# VPAC0_COMMON_0_IVPAC_TOP_0_CFG_SLV_PAR_VPAC_VISS0_S_VBUSP_MMR_CFG_VISS_TOP register map
Vendor: Texas Instruments
Peripheral module from a debugger description file (folder am62A).
Registers are 32-bit, read-write, reset 0x0 unless marked. A register's access mark holds for its fields unless they carry their own. Offsets are as the file gives them; lines under a group give offsets from that group; [hi:lo] are bit positions; {n}, {i} and the like mark numbered series; 'fields as' and 'values as' point back to an identical list; <NAME> marks a mode.

## VPAC0_COMMON_0_IVPAC_TOP_0_CFG_SLV_PAR_VPAC_VISS0_S_VBUSP_MMR_CFG_VISS_TOP
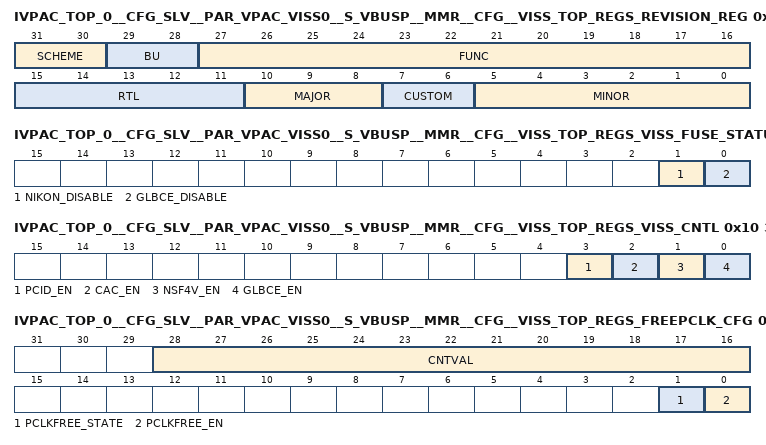
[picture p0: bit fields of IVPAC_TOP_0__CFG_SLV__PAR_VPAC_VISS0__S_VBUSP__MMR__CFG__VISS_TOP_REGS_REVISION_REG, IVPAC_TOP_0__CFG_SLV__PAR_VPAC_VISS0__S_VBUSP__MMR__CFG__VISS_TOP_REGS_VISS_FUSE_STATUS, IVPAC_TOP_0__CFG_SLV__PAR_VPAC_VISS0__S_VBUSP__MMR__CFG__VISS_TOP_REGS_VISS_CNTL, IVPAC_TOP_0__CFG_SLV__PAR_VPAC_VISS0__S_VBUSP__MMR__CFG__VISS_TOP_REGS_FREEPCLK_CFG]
0x00 IVPAC_TOP_0__CFG_SLV__PAR_VPAC_VISS0__S_VBUSP__MMR__CFG__VISS_TOP_REGS_REVISION_REG ro reset 0x64C40200 — VISS PID
  [31:30] SCHEME — Used to distinguish between old scheme and new scheme. Spare bit to encode future schemes
  [29:28] BU — BU indicator DSPS ==> 0x0 WTBU ==> 0x1 Processors ==> 0x2
  [27:16] FUNC — Function indicates a software compatible module family. If there is no level of software compatibility a new FUNC number, and hence PID, should be assigned.
  [15:11] RTL — RTL Version. R as described in PDR with additional clarifications and definitions below. Must be easily ECO-able or controlled during fabrication. Ideally through a top level metal mask or e-fuse. This number is maintained/owned by IP design owner. RTL follows a numbering such as X.Y.R.Z which are explained in this table. R changes ONLY when: (1) PDS uploads occur which may have been due to spec changes (2) Bug fixes occur (3) Resets to '0' when X or Y changes. Design team has an internal 'Z' (customer invisible) number which increments on every drop that happens due to DV and RTL updates. Z resets to 0 when R increments.
  [10:8] MAJOR — Major Revision. X as described in PDR with additional clarifications/definitions below. This number is owned/maintained by IP specification owner. X is part of IP numbering X.Y.R.Z. X changes ONLY when: (1) There is a major feature addition. An example would be adding Master Mode to Utopia Level2. The Func field (or Class/Type in old PID format) will remain the same. X does NOT change due to: (1) Bug fixes (2) Change in feature parameters.
  [7:6] CUSTOM — Indicates a special version for a particular device. Consequence of use may avoid use of standard Chip Support Library (CSL) / Drivers. 0 if non-custom.
  [5:0] MINOR — Minor Revision. Y as described in PDR with additional clarifications/definitions below. This number is owned/maintained by IP specification owner. Y changes ONLY when: (1) Features are scaled (up or down). Flexibility exists in that this feature scalability may either be represented in the Y change or a specific register in the IP that indicates which features are exactly available. (2) When feature creeps from Is-Not list to Is list. But this may not be the case once it sees silicon - in which case X will change. Y does NOT change due to: (1) Bug fixes (2) Typos or clarifications (3) major functional/feature change/addition/deletion. Instead these changes may be reflected via R, S, X as applicable. Spec owner maintains a customer-invisible number 'S' which changes due to: (1) Typos/clarifications (2) Bug documentation. Note that this bug is not due to a spec change but due to implementation. Nevertheless, the spec tracks the IP bugs. An RTL release (say for silicon PG1.1) that occurs due to bug fix should document the corresponding spec number (X.Y.S) in its release notes.
0x04 IVPAC_TOP_0__CFG_SLV__PAR_VPAC_VISS0__S_VBUSP__MMR__CFG__VISS_TOP_REGS_VISS_FUSE_STATUS ro — Register captures the Fuse control status. Shouldn't be captured into TRM
  [1] NIKON_DISABLE — Availability of NIKON specific feature HW in H3A. '0' -> Nikon features are available '1' -> Nikon features are not available
  [0] GLBCE_DISABLE — Availability GLBCE HW. '0' -> GLBCE function HW is available '1' -> GLBCE function HW is not available
0x08 IVPAC_TOP_0__CFG_SLV__PAR_VPAC_VISS0__S_VBUSP__MMR__CFG__VISS_TOP_REGS_VISS_LINEMEM_SIZE ro reset 0x1000 — Captures the no. of pixels per line supported by the VISS
  [13:0] LINEMEM_SZ — No. of pixels per line supported by the VISS HWAs Memories
0x0C IVPAC_TOP_0__CFG_SLV__PAR_VPAC_VISS0__S_VBUSP__MMR__CFG__VISS_TOP_REGS_SYSCONFIG — system Configuration
  [1] CLKCG_OVERIDE — Reserved for this HW version
0x10 IVPAC_TOP_0__CFG_SLV__PAR_VPAC_VISS0__S_VBUSP__MMR__CFG__VISS_TOP_REGS_VISS_CNTL — VISS top control
  [3] PCID_EN — '1' -> PCID is ON , '0' -> PCID is off i.e. bypass PCID. Read the bit status for completion of write. Even when '0', Configuration access to PCID will be successful.
  [2] CAC_EN — '1' -> CAC is ON , '0' -> CAC is off i.e. bypass CAC. Read the bit status for completion of write. Even when '0', Configuration access to CAC will be successful.
  [1] NSF4V_EN — '1' -> NSF4V is ON , '0' -> NSF4V is off i.e. bypass NSF4V. Read the bit status for completion of write. Even when '0', Configuration access to NSF4V will be successful.
  [0] GLBCE_EN — '1' -> GLBCE is ON , '0' -> GLBCE is off i.e. bypass GLBCE. Read the bit status for completion of write. When '0', Configuration access to GLBCE End points (MMR, Statastics memory ) will result in Error response.
0x14 IVPAC_TOP_0__CFG_SLV__PAR_VPAC_VISS0__S_VBUSP__MMR__CFG__VISS_TOP_REGS_FREEPCLK_CFG access per field — Register to control and configure Free running pixel clock to whole VISS pipe line
  [28:16] CNTVAL rw — Number of free pixel clocks to be provided
  [1] PCLKFREE_STATE ro — Status of Free running pixel clock state. 0 - Free running pixel Clock is not being provided currently 1 - Free running pixel Clock is getting provided
  [0] PCLKFREE_EN rw — Enable to provide Free running pixel clocks at the end of frame for VISS data pipe line. Needs to be enabled before end of a frame to provide free running pixel clock after that particular frame
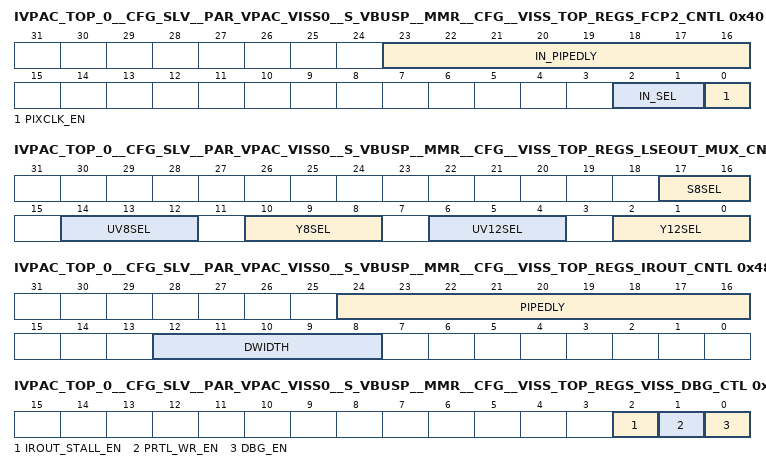
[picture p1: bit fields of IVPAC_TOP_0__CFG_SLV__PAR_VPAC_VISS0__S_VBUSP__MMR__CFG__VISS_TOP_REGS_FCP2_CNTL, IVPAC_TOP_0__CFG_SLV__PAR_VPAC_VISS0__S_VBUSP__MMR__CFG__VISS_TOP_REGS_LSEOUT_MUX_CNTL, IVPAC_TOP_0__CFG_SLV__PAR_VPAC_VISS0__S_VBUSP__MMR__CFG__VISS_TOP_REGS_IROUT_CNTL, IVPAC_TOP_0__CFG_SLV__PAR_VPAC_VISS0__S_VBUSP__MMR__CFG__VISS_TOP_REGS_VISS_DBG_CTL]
0x40 IVPAC_TOP_0__CFG_SLV__PAR_VPAC_VISS0__S_VBUSP__MMR__CFG__VISS_TOP_REGS_FCP2_CNTL — FCP2 Input Control register
  [23:16] IN_PIPEDLY — No. of pixel clock pipe delay on FCP2 input Vport. Used for matching with horizontal delay upto FCP Input
  [2:1] IN_SEL — Input path to FCP2. 0 - RFE output 1 - NSF4V output 2 - GLBCE output 3 - CAC output
  [0] PIXCLK_EN — Enable for FCP2 Pixel clock. 0 - FCP2 Pixel clock gated 1 - Pixel clock is enabled for FCP2
0x44 IVPAC_TOP_0__CFG_SLV__PAR_VPAC_VISS0__S_VBUSP__MMR__CFG__VISS_TOP_REGS_LSEOUT_MUX_CNTL reset 0x2200 — LSE Outout channel mux contro. IR output[11:0] selection should be used when IR output width <= 12. When IR data width is greater than 12-bit, it should split & LSB, MSB send across Y and UV channels to merge in LSE
  [17:16] S8SEL — LSE[4] - S8 output channel driver. 0 - FCP S8 Channel 1 - Reserved 2 - PCID IR Channel output[11:0] (IR data width is 8-12bit range) Others - In valid
  [14:12] UV8SEL — LSE[3] - UV8 output channel driver. 0 - Reserved 1 - Reserved 2 - FCP UV8 Channel 3 - Reserved 4 - PCID IR Channel output[11:0] (IR data width is 8-12bit range) 5 - PCID IR Channel output[7:0] (when IR data width > 12) Others - In valid
  [10:8] Y8SEL — LSE[2] - Y8 output channel driver. 0 - Reserved 1 - Reserved 2 - FCP Y8 Channel 3 - Reserved 4 - PCID IR Channel output[11:0] (IR data width is 8-12bit range) 5 - PCID IR Channel output[15:8] (when IR data width > 12) Others - In valid
  [6:4] UV12SEL — LSE[1] - UV12 output channel driver. 0 - FCP UV12 Channel 1 - Reserved 2 - Reserved 3 - Reserved 4 - PCID IR Channel output[11:0] (IR data width is 8-12bit range) 5 - PCID IR Channel output[7:0] (when IR data width > 12) Others - In valid
  [2:0] Y12SEL — LSE[0] - Y12 output channel driver. 0 - FCP Y12 Channel 1 - Reserved 2 - Reserved 3 - Reserved 4 - PCID IR Channel output[11:0] (IR data width is 8-12bit range) 5 - PCID IR Channel output[15:8] (when IR data width > 12) Others - In valid
0x48 IVPAC_TOP_0__CFG_SLV__PAR_VPAC_VISS0__S_VBUSP__MMR__CFG__VISS_TOP_REGS_IROUT_CNTL reset 0xC00 — Control register for IR Output path delay synchronization with rest of the pipe line
  [24:16] PIPEDLY — No. of pixel clock pipe delay on PCID IR Output channel. Max allowed value is 274. Used for matching horizontal delay VISS bayer pipe line
  [12:8] DWIDTH — IR Output Data width. Valid ranges are 8-16
0x70 IVPAC_TOP_0__CFG_SLV__PAR_VPAC_VISS0__S_VBUSP__MMR__CFG__VISS_TOP_REGS_VISS_INT_STAT access not given — Set on internal interutp event and clr by SW
  [0] IROUT_OVF_ERR — Status/Clear for Overflow on IR output write infrace. Set on Overflow condition on IR output interface (access R/W1TC)
0x80 IVPAC_TOP_0__CFG_SLV__PAR_VPAC_VISS0__S_VBUSP__MMR__CFG__VISS_TOP_REGS_VISS_DBG_CTL — Enable for VISS debug staus capture
  [2] IROUT_STALL_EN — Enable to Capture Stall on IR output write infrace
  [1] PRTL_WR_EN — Enable to Capture Partial Write to any VISS end point
  [0] DBG_EN — Enable debug features, set to '0' to disable all debug events
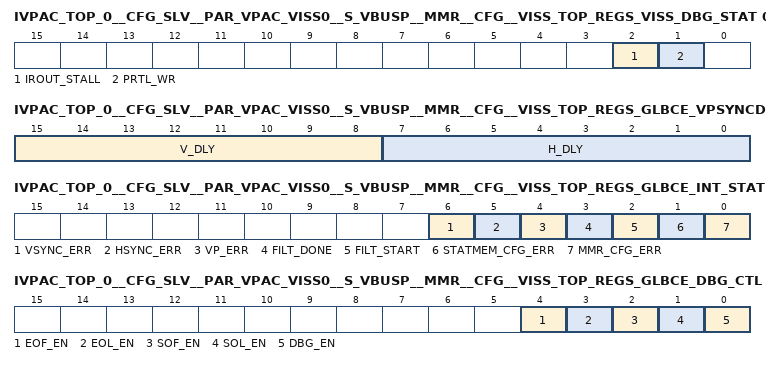
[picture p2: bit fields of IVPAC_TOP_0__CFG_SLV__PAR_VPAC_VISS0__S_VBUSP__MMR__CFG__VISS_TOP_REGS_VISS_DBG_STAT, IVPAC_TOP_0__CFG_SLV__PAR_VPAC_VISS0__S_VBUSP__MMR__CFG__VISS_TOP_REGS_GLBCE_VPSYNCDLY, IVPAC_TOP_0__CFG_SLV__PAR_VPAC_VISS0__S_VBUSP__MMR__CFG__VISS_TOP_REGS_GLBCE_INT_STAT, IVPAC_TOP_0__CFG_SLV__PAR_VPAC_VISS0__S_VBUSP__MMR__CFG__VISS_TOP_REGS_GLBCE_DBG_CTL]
0x84 IVPAC_TOP_0__CFG_SLV__PAR_VPAC_VISS0__S_VBUSP__MMR__CFG__VISS_TOP_REGS_VISS_DBG_STAT access not given — Set/Clear for VISS debug status
  [2] IROUT_STALL — Status/Clear for Stall on IR output write infrace. Set on stall IR output interface (access R/W1TC)
  [1] PRTL_WR — Status/Clear for Partial Write to any VISS end point. Set on Partial Write at VISS_Top input Cfg interface (access R/W1TC)
0x100 IVPAC_TOP_0__CFG_SLV__PAR_VPAC_VISS0__S_VBUSP__MMR__CFG__VISS_TOP_REGS_GLBCECONFIG — GLBCE Configuration
  [0] GLBCE_PCLKFREE — '1'-> GLBCE pclk is free running , '0' -> GLBCE pclk is gated pixel clock
0x104 IVPAC_TOP_0__CFG_SLV__PAR_VPAC_VISS0__S_VBUSP__MMR__CFG__VISS_TOP_REGS_GLBCE_VPSYNCDLY reset 0x13C — Delay of GLBCE Core, used to regenerate VS/VE VPORT signals
  [15:8] V_DLY — Line delay between GLBCE.VS_In to GLBCE.VS_Out
  [7:0] H_DLY — Cycle delay between GLBCE.HS_In to GLBCE.HS_Out minus 1
0x108 IVPAC_TOP_0__CFG_SLV__PAR_VPAC_VISS0__S_VBUSP__MMR__CFG__VISS_TOP_REGS_GLBCE_INT_STAT access not given — Set on internal interutp event and clr by SW
  [6] VSYNC_ERR — status/clear for GLBCE VSYNC Delay programmation error. Set Delayed sync signals doesn't match with sync signal generated from GLBCE Core (access R/W1TC)
  [5] HSYNC_ERR — status/clear for GLBCE HSYNC Delay programmation error. Set Delayed sync signals doesn't match with sync signal generated from GLBCE Core (access R/W1TC)
  [4] VP_ERR — status/clear for GLBCE Input frame start error. Set Input frame is started while filtering is going on (access R/W1TC)
  [3] FILT_DONE — status/clear for GLBCE Filtering Done event. Set when GLBCE Filtering is completed. (access R/W1TC)
  [2] FILT_START — status/clear for GLBCE Filtering Start event. Set when GLBCE Filtering starts (access R/W1TC)
  [1] STATMEM_CFG_ERR — status/clear for statastics memory configuration error. Set when access happen to statastics memory in the middle of processing (access R/W1TC)
  [0] MMR_CFG_ERR — status/clear for mmr configuration error. Set when writes happen to non-shadowed registers in the middle of processing (access R/W1TC)
0x10C IVPAC_TOP_0__CFG_SLV__PAR_VPAC_VISS0__S_VBUSP__MMR__CFG__VISS_TOP_REGS_GLBCE_DBG_CTL — Enable for GLBCE debug events
  [4] EOF_EN — Enable for EOF at GLBCE output
  [3] EOL_EN — Enable for EOL at GLBCE output
  [2] SOF_EN — Enable for SOF at GLBCE input
  [1] SOL_EN — Enable for SOL at GLBCE input
  [0] DBG_EN — Enable debug features, set to '0' to disable all debug events
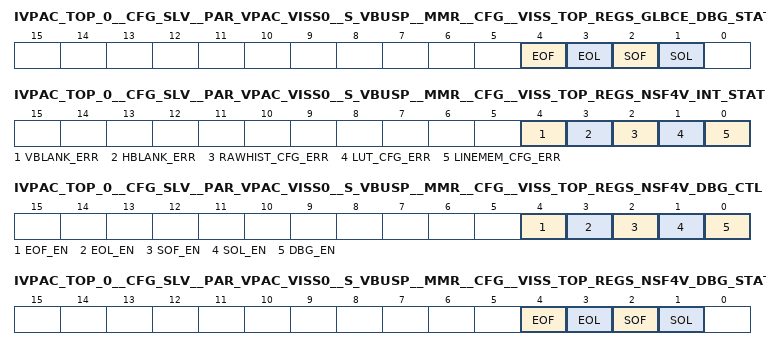
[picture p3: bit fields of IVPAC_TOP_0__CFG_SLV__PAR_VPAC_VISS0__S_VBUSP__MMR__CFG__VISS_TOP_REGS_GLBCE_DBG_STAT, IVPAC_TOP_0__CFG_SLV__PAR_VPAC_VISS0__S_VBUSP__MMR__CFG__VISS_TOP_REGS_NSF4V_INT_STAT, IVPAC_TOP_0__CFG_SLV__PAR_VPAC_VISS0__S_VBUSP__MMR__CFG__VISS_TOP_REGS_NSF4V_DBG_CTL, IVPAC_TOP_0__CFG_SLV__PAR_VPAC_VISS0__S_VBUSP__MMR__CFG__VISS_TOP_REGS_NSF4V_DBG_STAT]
0x110 IVPAC_TOP_0__CFG_SLV__PAR_VPAC_VISS0__S_VBUSP__MMR__CFG__VISS_TOP_REGS_GLBCE_DBG_STAT access not given — Set/Clear for GLBCE debug events
  [4] EOF — Status/Clear for EOF at GLBCE output. Set on EOF at GLBCE output (access R/W1TC)
  [3] EOL — Status/Clear for EOL at GLBCE output. Set on EOL at GLBCE output (access R/W1TC)
  [2] SOF — Status/Clear for SOF at GLBCE input. Set on SOF at GLBCE input (access R/W1TC)
  [1] SOL — Status/Clear for SOL at GLBCE input. Set on SOL at GLBCE input (access R/W1TC)
0x180 IVPAC_TOP_0__CFG_SLV__PAR_VPAC_VISS0__S_VBUSP__MMR__CFG__VISS_TOP_REGS_NSF4V_INT_STAT access not given — Set on internal interutp event and clr by SW
  [4] VBLANK_ERR — status/clear for Vorizontal Blanking Error. Set when Vertical Blanking too short between frames (access R/W1TC)
  [3] HBLANK_ERR — status/clear for Horizontal Blanking Error. Set when Horzontal Blanking too short between lines (access R/W1TC)
  [2] RAWHIST_CFG_ERR — status/clear for RawHistogram Read incomplete. Set when SW starts reading Raw Histogram data (read from location '0') but didn't complete (read from '127' location) before end of next frame (access R/W1TC)
  [1] LUT_CFG_ERR — status/clear for Histogram LUT memory configuration error. Set VBUSP access of RAM while NSF data path using LUT for functional purpose (access R/W1TC)
  [0] LINEMEM_CFG_ERR — status/clear for Line mem configuration error. Set when VBUSP diagnostic read access of RAM while NSF data path using RAM for functional purpose (access R/W1TC)
0x184 IVPAC_TOP_0__CFG_SLV__PAR_VPAC_VISS0__S_VBUSP__MMR__CFG__VISS_TOP_REGS_NSF4V_DBG_CTL — Enable for NSF4V debug events
  [4] EOF_EN — Enable for EOF at NSF4V output
  [3] EOL_EN — Enable for EOL at NSF4V output
  [2] SOF_EN — Enable for SOF at NSF4V input
  [1] SOL_EN — Enable for SOL at NSF4V input
  [0] DBG_EN — Enable debug features, set to '0' to disable all debug events
0x188 IVPAC_TOP_0__CFG_SLV__PAR_VPAC_VISS0__S_VBUSP__MMR__CFG__VISS_TOP_REGS_NSF4V_DBG_STAT access not given — Set/Clear for NSF4V debug events
  [4] EOF — Status/Clear for EOF at NSF4V output. Set on EOF at NSF4V output (access R/W1TC)
  [3] EOL — Status/Clear for EOL at NSF4V output. Set on EOL at NSF4V output (access R/W1TC)
  [2] SOF — Status/Clear for SOF at NSF4V input. Set on SOF at NSF4V input (access R/W1TC)
  [1] SOL — Status/Clear for SOL at NSF4V input. Set on SOL at NSF4V input (access R/W1TC)
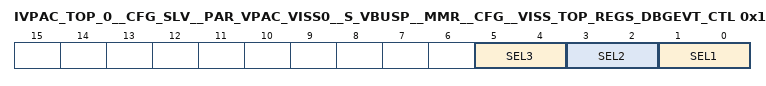
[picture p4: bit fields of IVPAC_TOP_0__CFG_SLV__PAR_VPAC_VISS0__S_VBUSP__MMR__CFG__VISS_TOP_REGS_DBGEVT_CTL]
0x1A0 IVPAC_TOP_0__CFG_SLV__PAR_VPAC_VISS0__S_VBUSP__MMR__CFG__VISS_TOP_REGS_DBGEVT_CTL — Control to map internal events
  [5:4] SEL3 — Mux select for GLBCE CAC , PCID VPORT events. 0 - Select GLBCE events 1 - Select CAC events 2. Select PCID events Common mux control for SOL, SOF, EOL and EOF events between the GLBCE and CAC. For PCID output events IR VPORT is exported
  [3:2] SEL2 — Mux select for CFA SOFs and FCP2 fcc_eop event. 0 - FCP.cfa_sof_event 1 - reserved 2 - reserved 3. Invalid
  [1:0] SEL1 — Mux select for CFA SOLs , FCP2 fcc_stall and IR output write stall event. 0 - FCP.cfa_sol_event 1 - reserved 2 - reserved 3. PCID IR output write Stall
0x1C0 IVPAC_TOP_0__CFG_SLV__PAR_VPAC_VISS0__S_VBUSP__MMR__CFG__VISS_TOP_REGS_TEST_CNTL — Control register for TEST. Shouldn't be used in functional mode
  [0] GATED_MEM_CLKF — Control to force functional clock to H3A and CAC line memory for Pbist Config test. '1' - Free running functional clock is supplied to H3A line memory '0' - Gated Pixel clock is supplied in functional operation
